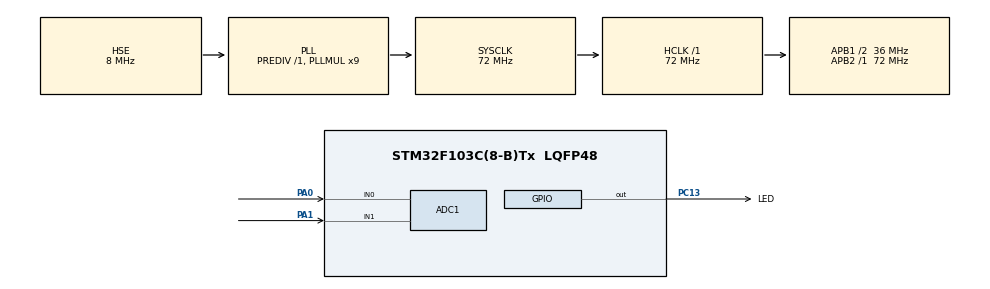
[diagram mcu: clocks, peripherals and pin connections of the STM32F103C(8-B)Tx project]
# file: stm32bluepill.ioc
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ADC1.Channel-0\#ChannelRegularConversion=ADC_CHANNEL_0
ADC1.Channel-1\#ChannelRegularConversion=ADC_CHANNEL_1
ADC1.ContinuousConvMode=ENABLE
ADC1.NbrOfConversion=2
ADC1.NbrOfConversionFlag=1
ADC1.Rank-0\#ChannelRegularConversion=1
ADC1.Rank-1\#ChannelRegularConversion=2
ADC1.SamplingTime-0\#ChannelRegularConversion=ADC_SAMPLETIME_239CYCLES_5
ADC1.SamplingTime-1\#ChannelRegularConversion=ADC_SAMPLETIME_239CYCLES_5
ADC1.master=1
Dma.ADC1.0.Direction=DMA_PERIPH_TO_MEMORY
Dma.ADC1.0.Instance=DMA1_Channel1
Dma.ADC1.0.MemDataAlignment=DMA_MDATAALIGN_WORD
Dma.ADC1.0.MemInc=DMA_MINC_ENABLE
Dma.ADC1.0.Mode=DMA_CIRCULAR
Dma.ADC1.0.PeriphDataAlignment=DMA_PDATAALIGN_WORD
Dma.ADC1.0.PeriphInc=DMA_PINC_DISABLE
Dma.ADC1.0.Priority=DMA_PRIORITY_LOW
Dma.Request0=ADC1
FREERTOS.Tasks01=defaultTask,24,128,StartDefaultTask,Default,NULL,Dynamic,NULL,NULL
FREERTOS.configUSE_NEWLIB_REENTRANT=1
Mcu.Family=STM32F1
Mcu.Name=STM32F103C(8-B)Tx
Mcu.Package=LQFP48
NVIC.ADC1_2_IRQn=true\:5\:0\:false\:false\:true\:true\:true\:true\:true
NVIC.DMA1_Channel1_IRQn=true\:5\:0\:false\:false\:true\:true\:false\:true\:true
NVIC.PriorityGroup=NVIC_PRIORITYGROUP_4
NVIC.TIM4_IRQn=true\:15\:0\:false\:false\:true\:false\:false\:true\:true
NVIC.TimeBase=TIM4_IRQn
NVIC.TimeBaseIP=TIM4
PA0-WKUP.Signal=ADCx_IN0
PA1.Signal=ADCx_IN1
PA13.Mode=Serial_Wire
PA13.Signal=SYS_JTMS-SWDIO
PA14.Mode=Serial_Wire
PA14.Signal=SYS_JTCK-SWCLK
PC13-TAMPER-RTC.GPIO_Label=LED
PC13-TAMPER-RTC.Signal=GPIO_Output
PD0-OSC_IN.Mode=HSE-External-Oscillator
PD0-OSC_IN.Signal=RCC_OSC_IN
PD1-OSC_OUT.Mode=HSE-External-Oscillator
PD1-OSC_OUT.Signal=RCC_OSC_OUT
ProjectManager.HeapSize=0x200
ProjectManager.StackSize=0x400
ProjectManager.TargetToolchain=STM32CubeIDE
RCC.ADCPresc=RCC_ADCPCLK2_DIV6
RCC.AHBFreq_Value=72000000
RCC.APB1CLKDivider=RCC_HCLK_DIV2
RCC.APB1Freq_Value=36000000
RCC.APB1TimFreq_Value=72000000
RCC.APB2Freq_Value=72000000
RCC.APB2TimFreq_Value=72000000
RCC.HCLKFreq_Value=72000000
RCC.PLLMUL=RCC_PLL_MUL9
RCC.PLLSourceVirtual=RCC_PLLSOURCE_HSE
RCC.SYSCLKFreq_VALUE=72000000
RCC.SYSCLKSource=RCC_SYSCLKSOURCE_PLLCLK
RCC.USBFreq_Value=72000000
SH.ADCx_IN0.0=ADC1_IN0,IN0
SH.ADCx_IN1.0=ADC1_IN1,IN1
VP_FREERTOS_VS_CMSIS_V2.Mode=CMSIS_V2
VP_SYS_VS_tim4.Mode=TIM4
board=custom

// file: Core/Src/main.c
/* USER CODE BEGIN Header */
/**
  ******************************************************************************
  * @file           : main.c
  * @brief          : Main program body
  ******************************************************************************
  * @attention
  *
  * Copyright (c) 2024 STMicroelectronics.
  * All rights reserved.
  *
  * This software is licensed under terms that can be found in the LICENSE file
  * in the root directory of this software component.
  * If no LICENSE file comes with this software, it is provided AS-IS.
  *
  ******************************************************************************
  */
/* USER CODE END Header */
#include "main.h"
#include "cmsis_os.h"

/* USER CODE BEGIN Includes */
#include "stdio.h"
#include "string.h"
/* USER CODE END Includes */

/* USER CODE BEGIN PD */
#define VREF 3.3f
#define ADC_N_CHANNEL 2
#define RSHUNT 0.001f
#define GAIN 20
/* USER CODE END PD */

ADC_HandleTypeDef hadc1;
DMA_HandleTypeDef hdma_adc1;

/* Definitions for defaultTask */
osThreadId_t defaultTaskHandle;
const osThreadAttr_t defaultTask_attributes = {
  .name = "defaultTask",
  .stack_size = 128 * 4,
  .priority = (osPriority_t) osPriorityNormal,
};
/* USER CODE BEGIN PV */
float lux = 0;
float pot = 0;
//uint16_t rawValue[2];
char msg[20];

static volatile float volts[ADC_N_CHANNEL];
static uint32_t adc_buffer[ADC_N_CHANNEL];
float sample;
float pref_sample;
float current;

/* USER CODE END PV */

void SystemClock_Config(void);
static void MX_GPIO_Init(void);
static void MX_DMA_Init(void);
static void MX_ADC1_Init(void);
void StartDefaultTask(void *argument);

/* USER CODE BEGIN 0 */
uint8_t convComplete = 0;

void HAL_ADC_ConvCpltCallback(ADC_HandleTypeDef* hadc)
{
    if (hadc->Instance == hadc1.Instance) {
        for (int i = 0; i < ADC_N_CHANNEL; ++i) {
        	lux = adc_buffer[0];
        	pot = adc_buffer[1];
            float pref_sample = volts[i] / 1000.f;
            float sample = (float)adc_buffer[i] * VREF / (float)(1 << 12) / 1000.f;
            volts[i] = pref_sample * 999.f + sample;
//            lux = volts[0];
//            pot = volts[1];
//            current = (volts[i]-VREF/2)/GAIN/RSHUNT;
//            convComplete = 1;
        }
    }
}

/* USER CODE END 0 */

int main(void)
{

  /* MCU Configuration--------------------------------------------------------*/

  /* Reset of all peripherals, Initializes the Flash interface and the Systick. */
  HAL_Init();

  /* Configure the system clock */
  SystemClock_Config();

  /* Initialize all configured peripherals */
  MX_GPIO_Init();
  MX_DMA_Init();
  MX_ADC1_Init();

  /* Init scheduler */
  osKernelInitialize();

  /* Create the thread(s) */
  /* creation of defaultTask */
  defaultTaskHandle = osThreadNew(StartDefaultTask, NULL, &defaultTask_attributes);

  /* Start scheduler */
  osKernelStart();

  /* We should never get here as control is now taken by the scheduler */

  /* Infinite loop */
  while (1)
  {

  }
}

void SystemClock_Config(void)
{
  RCC_OscInitTypeDef RCC_OscInitStruct = {0};
  RCC_ClkInitTypeDef RCC_ClkInitStruct = {0};
  RCC_PeriphCLKInitTypeDef PeriphClkInit = {0};

  /** Initializes the RCC Oscillators according to the specified parameters
  * in the RCC_OscInitTypeDef structure.
  */
  RCC_OscInitStruct.OscillatorType = RCC_OSCILLATORTYPE_HSE;
  RCC_OscInitStruct.HSEState = RCC_HSE_ON;
  RCC_OscInitStruct.HSEPredivValue = RCC_HSE_PREDIV_DIV1;
  RCC_OscInitStruct.HSIState = RCC_HSI_ON;
  RCC_OscInitStruct.PLL.PLLState = RCC_PLL_ON;
  RCC_OscInitStruct.PLL.PLLSource = RCC_PLLSOURCE_HSE;
  RCC_OscInitStruct.PLL.PLLMUL = RCC_PLL_MUL9;
  if (HAL_RCC_OscConfig(&RCC_OscInitStruct) != HAL_OK)
  {
    Error_Handler();
  }

  /** Initializes the CPU, AHB and APB buses clocks
  */
  RCC_ClkInitStruct.ClockType = RCC_CLOCKTYPE_HCLK|RCC_CLOCKTYPE_SYSCLK
                              |RCC_CLOCKTYPE_PCLK1|RCC_CLOCKTYPE_PCLK2;
  RCC_ClkInitStruct.SYSCLKSource = RCC_SYSCLKSOURCE_PLLCLK;
  RCC_ClkInitStruct.AHBCLKDivider = RCC_SYSCLK_DIV1;
  RCC_ClkInitStruct.APB1CLKDivider = RCC_HCLK_DIV2;
  RCC_ClkInitStruct.APB2CLKDivider = RCC_HCLK_DIV1;

  if (HAL_RCC_ClockConfig(&RCC_ClkInitStruct, FLASH_LATENCY_2) != HAL_OK)
  {
    Error_Handler();
  }
  PeriphClkInit.PeriphClockSelection = RCC_PERIPHCLK_ADC;
  PeriphClkInit.AdcClockSelection = RCC_ADCPCLK2_DIV6;
  if (HAL_RCCEx_PeriphCLKConfig(&PeriphClkInit) != HAL_OK)
  {
    Error_Handler();
  }
}

static void MX_ADC1_Init(void)
{

  ADC_ChannelConfTypeDef sConfig = {0};

  /** Common config
  */
  hadc1.Instance = ADC1;
  hadc1.Init.ScanConvMode = ADC_SCAN_ENABLE;
  hadc1.Init.ContinuousConvMode = ENABLE;
  hadc1.Init.DiscontinuousConvMode = DISABLE;
  hadc1.Init.ExternalTrigConv = ADC_SOFTWARE_START;
  hadc1.Init.DataAlign = ADC_DATAALIGN_RIGHT;
  hadc1.Init.NbrOfConversion = 2;
  if (HAL_ADC_Init(&hadc1) != HAL_OK)
  {
    Error_Handler();
  }

  /** Configure Regular Channel
  */
  sConfig.Channel = ADC_CHANNEL_0;
  sConfig.Rank = ADC_REGULAR_RANK_1;
  sConfig.SamplingTime = ADC_SAMPLETIME_239CYCLES_5;
  if (HAL_ADC_ConfigChannel(&hadc1, &sConfig) != HAL_OK)
  {
    Error_Handler();
  }

  /** Configure Regular Channel
  */
  sConfig.Channel = ADC_CHANNEL_1;
  sConfig.Rank = ADC_REGULAR_RANK_2;
  if (HAL_ADC_ConfigChannel(&hadc1, &sConfig) != HAL_OK)
  {
    Error_Handler();
  }

}

static void MX_DMA_Init(void)
{

  /* DMA controller clock enable */
  __HAL_RCC_DMA1_CLK_ENABLE();

  /* DMA interrupt init */
  /* DMA1_Channel1_IRQn interrupt configuration */
  HAL_NVIC_SetPriority(DMA1_Channel1_IRQn, 5, 0);
  HAL_NVIC_EnableIRQ(DMA1_Channel1_IRQn);

}

static void MX_GPIO_Init(void)
{
  GPIO_InitTypeDef GPIO_InitStruct = {0};

  /* GPIO Ports Clock Enable */
  __HAL_RCC_GPIOC_CLK_ENABLE();
  __HAL_RCC_GPIOD_CLK_ENABLE();
  __HAL_RCC_GPIOA_CLK_ENABLE();

  /*Configure GPIO pin Output Level */
  HAL_GPIO_WritePin(LED_GPIO_Port, LED_Pin, GPIO_PIN_RESET);

  /*Configure GPIO pin : LED_Pin */
  GPIO_InitStruct.Pin = LED_Pin;
  GPIO_InitStruct.Mode = GPIO_MODE_OUTPUT_PP;
  GPIO_InitStruct.Pull = GPIO_NOPULL;
  GPIO_InitStruct.Speed = GPIO_SPEED_FREQ_LOW;
  HAL_GPIO_Init(LED_GPIO_Port, &GPIO_InitStruct);

}

void StartDefaultTask(void *argument)
{
  /* USER CODE BEGIN 5 */
	HAL_ADC_Start_DMA(&hadc1, adc_buffer, ADC_N_CHANNEL);
	 __HAL_DMA_DISABLE_IT(hadc1.DMA_Handle, DMA_IT_HT); // disable half complete
  /* Infinite loop */
  for(;;)
  {
//	  while(!convComplete);
//	  for (uint8_t i = 0; i < hadc1.Init.NbrOfConversion; i++)
//	  {
//
//	  }

    osDelay(1);
  }
  /* USER CODE END 5 */
}

void HAL_TIM_PeriodElapsedCallback(TIM_HandleTypeDef *htim)
{
  if (htim->Instance == TIM4) {
    HAL_IncTick();
  }
}

void Error_Handler(void)
{
  __disable_irq();
  while (1)
  {
  }
}
